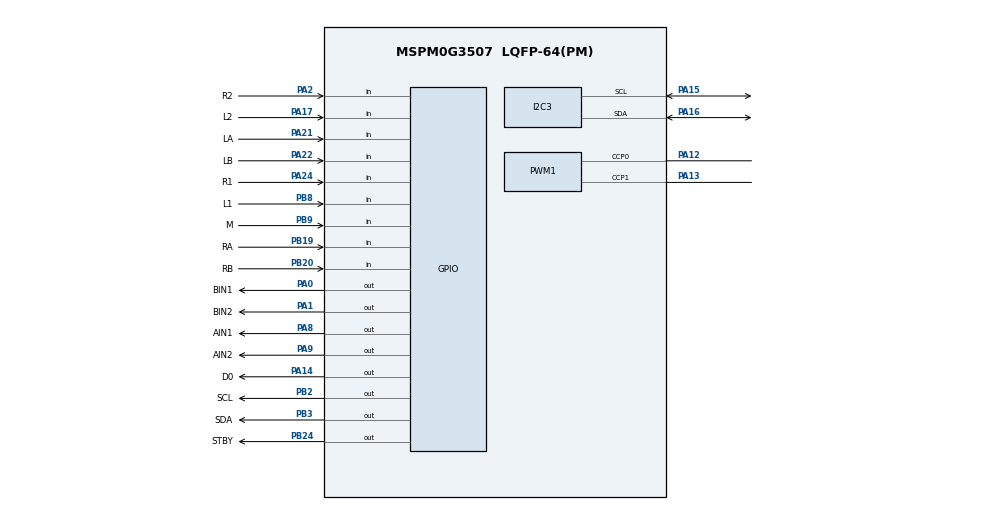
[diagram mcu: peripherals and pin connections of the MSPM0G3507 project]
/**
 * @cliArgs --device "MSPM0G350X" --part "Default" --package "LQFP-64(PM)" --product "mspm0_sdk@2.10.00.04"
 * @v2CliArgs --device "MSPM0G3507" --package "LQFP-64(PM)" --product "mspm0_sdk@2.10.00.04"
 * @versions {"tool":"1.26.2+4477"}
 */
const GPIO   = scripting.addModule("/ti/driverlib/GPIO", {}, false);
const GPIO1  = GPIO.addInstance();
const GPIO2  = GPIO.addInstance();
const GPIO3  = GPIO.addInstance();
const GPIO4  = GPIO.addInstance();
const I2C    = scripting.addModule("/ti/driverlib/I2C", {}, false);
const I2C3   = I2C.addInstance();
const PWM    = scripting.addModule("/ti/driverlib/PWM", {}, false);
const PWM1   = PWM.addInstance();
const SYSCTL = scripting.addModule("/ti/driverlib/SYSCTL");
const TIMER  = scripting.addModule("/ti/driverlib/TIMER", {}, false);
const TIMER1 = TIMER.addInstance();

// 时钟树 80MHz
const divider9 = system.clockTree["UDIV"];
divider9.divideValue = 2;
const multiplier2 = system.clockTree["PLL_QDIV"];
multiplier2.multiplyValue = 5;
const mux4 = system.clockTree["EXHFMUX"];
mux4.inputSelect = "EXHFMUX_XTAL";
const mux8 = system.clockTree["HSCLKMUX"];
mux8.inputSelect = "HSCLKMUX_SYSPLL0";
const pinFunction4 = system.clockTree["HFXT"];
pinFunction4.inputFreq = 40;
pinFunction4.enable = true;

const Board = scripting.addModule("/ti/driverlib/Board", {}, false);

// LED
GPIO1.$name = "LED";
GPIO1.associatedPins[0].$name = "D0";
GPIO1.associatedPins[0].pin.$assign = "PA14";

// I2C GPIO 模拟（OLED，PB2/PB3）
GPIO2.$name = "I2C";
GPIO2.associatedPins.create(2);
GPIO2.associatedPins[0].$name = "SDA";
GPIO2.associatedPins[0].initialValue = "SET";
GPIO2.associatedPins[0].pin.$assign = "PB3";
GPIO2.associatedPins[1].$name = "SCL";
GPIO2.associatedPins[1].initialValue = "SET";
GPIO2.associatedPins[1].pin.$assign = "PB2";

// 电机方向 + TB6612 STBY + 编码器
GPIO3.$name = "DC_MOTOR";
GPIO3.associatedPins.create(9);
// 方向引脚 - 输出
GPIO3.associatedPins[0].$name = "AIN1";
GPIO3.associatedPins[0].pin.$assign = "PA8";
GPIO3.associatedPins[1].$name = "AIN2";
GPIO3.associatedPins[1].pin.$assign = "PA9";
GPIO3.associatedPins[2].$name = "BIN1";
GPIO3.associatedPins[2].pin.$assign = "PA0";
GPIO3.associatedPins[3].$name = "BIN2";
GPIO3.associatedPins[3].pin.$assign = "PA1";
GPIO3.associatedPins[4].$name = "STBY";
GPIO3.associatedPins[4].pin.$assign = "PB24";
// 左电机编码器 - 输入（E1 接 PA21/PA22）
GPIO3.associatedPins[5].$name = "LA";
GPIO3.associatedPins[5].direction = "INPUT";
GPIO3.associatedPins[5].interruptEn = true;
GPIO3.associatedPins[5].polarity = "RISE";
GPIO3.associatedPins[5].internalResistor = "PULL_DOWN";
GPIO3.associatedPins[5].pin.$assign = "PA21";
GPIO3.associatedPins[6].$name = "LB";
GPIO3.associatedPins[6].direction = "INPUT";
GPIO3.associatedPins[6].internalResistor = "PULL_DOWN";
GPIO3.associatedPins[6].pin.$assign = "PA22";
// 右电机编码器 - 输入（E2 接 PB19/PB20）
GPIO3.associatedPins[7].$name = "RA";
GPIO3.associatedPins[7].direction = "INPUT";
GPIO3.associatedPins[7].interruptEn = true;
GPIO3.associatedPins[7].polarity = "RISE";
GPIO3.associatedPins[7].internalResistor = "PULL_DOWN";
GPIO3.associatedPins[7].pin.$assign = "PB19";
GPIO3.associatedPins[8].$name = "RB";
GPIO3.associatedPins[8].direction = "INPUT";
GPIO3.associatedPins[8].internalResistor = "PULL_DOWN";
GPIO3.associatedPins[8].pin.$assign = "PB20";

// 5路循迹传感器
GPIO4.$name = "HUIDU";
GPIO4.associatedPins.create(5);
GPIO4.associatedPins[0].$name = "L2";
GPIO4.associatedPins[0].direction = "INPUT";
GPIO4.associatedPins[0].pin.$assign = "PA17";
GPIO4.associatedPins[1].$name = "L1";
GPIO4.associatedPins[1].direction = "INPUT";
GPIO4.associatedPins[1].pin.$assign = "PB8";
GPIO4.associatedPins[2].$name = "M";
GPIO4.associatedPins[2].direction = "INPUT";
GPIO4.associatedPins[2].pin.$assign = "PB9";
GPIO4.associatedPins[3].$name = "R1";
GPIO4.associatedPins[3].direction = "INPUT";
GPIO4.associatedPins[3].pin.$assign = "PA24";
GPIO4.associatedPins[4].$name = "R2";
GPIO4.associatedPins[4].direction = "INPUT";
GPIO4.associatedPins[4].pin.$assign = "PA2";

// MPU6050 陀螺仪 (I2C1, PA15=SCL, PA16=SDA)
I2C3.$name = "MPU6050";
I2C3.basicEnableController = true;
I2C3.peripheral.$assign = "I2C1";
I2C3.peripheral.sdaPin.$assign = "PA16";
I2C3.peripheral.sclPin.$assign = "PA15";

// 电机 PWM (TIMG0, 20kHz)
PWM1.timerStartTimer = true;
PWM1.timerCount = 4000;
PWM1.pwmMode = "EDGE_ALIGN_UP";
PWM1.$name = "PWMAB";
PWM1.peripheral.$assign = "TIMG0";
PWM1.peripheral.ccp0Pin.$assign = "PA12";
PWM1.peripheral.ccp1Pin.$assign = "PA13";
PWM1.PWM_CHANNEL_0.$name = "ti_driverlib_pwm_PWMTimerCC1";
PWM1.PWM_CHANNEL_1.$name = "ti_driverlib_pwm_PWMTimerCC2";

SYSCTL.forceDefaultClkConfig = true;
SYSCTL.clockTreeEn = true;

// 电机PID定时中断 (TIMA0, 10ms)
TIMER1.$name = "MOTOR_PID";
TIMER1.timerMode = "PERIODIC_UP";
TIMER1.timerClkPrescale = 100;
TIMER1.interrupts = ["LOAD"];
TIMER1.timerPeriod = "10ms";
TIMER1.peripheral.$assign = "TIMA0";

/**
 * Pinmux solution for unlocked pins/peripherals.
 */
pinFunction4.peripheral.$suggestSolution = "SYSCTL";
pinFunction4.peripheral.hfxInPin.$suggestSolution = "PA5";
pinFunction4.peripheral.hfxOutPin.$suggestSolution = "PA6";
Board.peripheral.$suggestSolution = "DEBUGSS";
Board.peripheral.swclkPin.$suggestSolution = "PA20";
Board.peripheral.swdioPin.$suggestSolution = "PA19";
